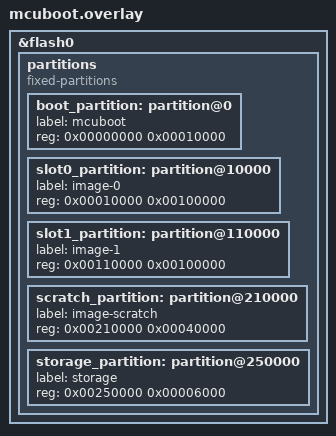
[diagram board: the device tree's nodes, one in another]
&flash0 {
/delete-node/ partitions;

partitions {
compatible = "fixed-partitions";
#address-cells = <1>;
#size-cells = <1>;

boot_partition: partition@0 {
label = "mcuboot";
reg = <0x00000000 0x00010000>;
};

slot0_partition: partition@10000 {
label = "image-0";
reg = <0x00010000 0x00100000>;
};

slot1_partition: partition@110000 {
label = "image-1";
reg = <0x00110000 0x00100000>;
};

scratch_partition: partition@210000 {
label = "image-scratch";
reg = <0x00210000 0x00040000>;
};

storage_partition: partition@250000 {
label = "storage";
reg = <0x00250000 0x00006000>;
};
};
};
